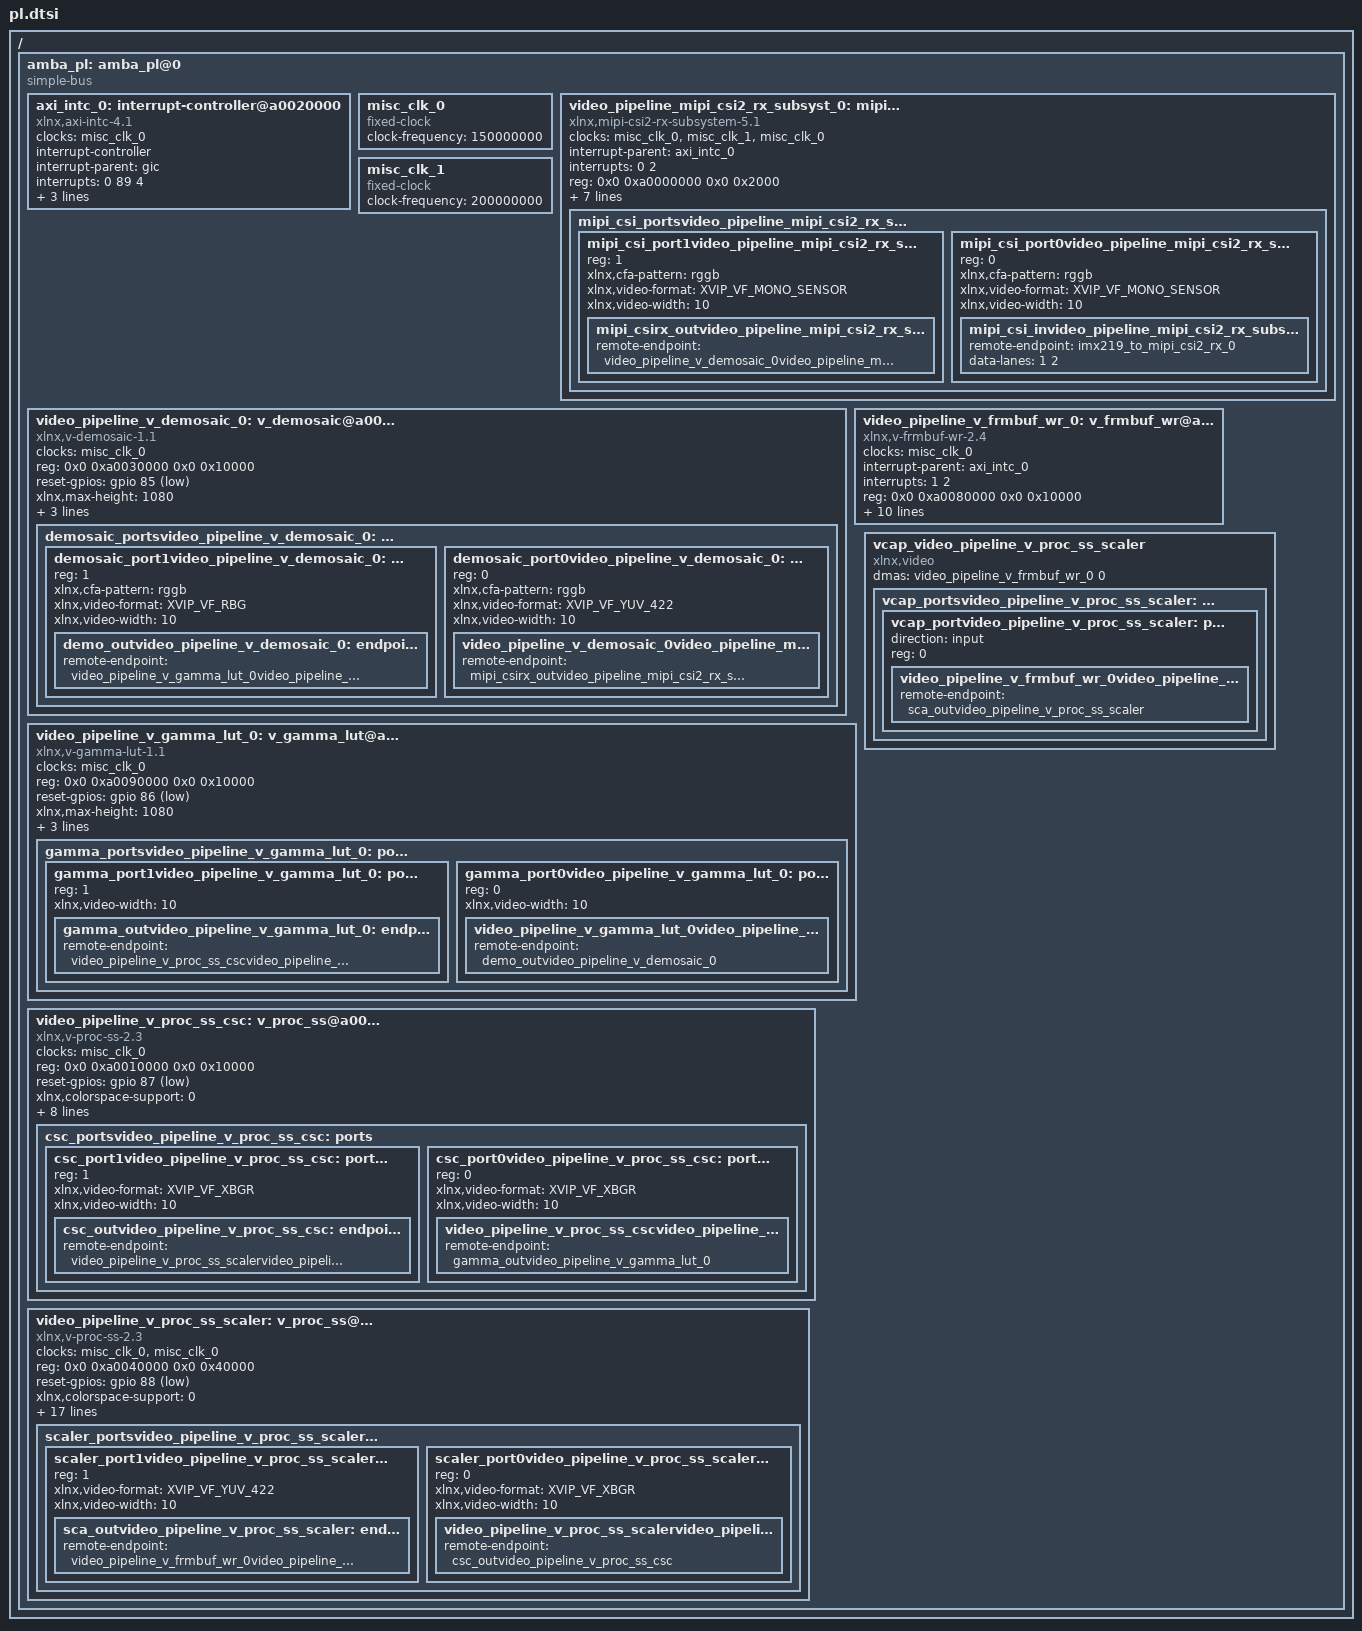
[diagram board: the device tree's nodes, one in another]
/*
 * CAUTION: This file is automatically generated by Xilinx.
 * Version: XSCT 2022.1
 * Today is: Tue Aug 23 20:26:12 2022
 */

#include <dt-bindings/media/xilinx-vip.h>

/ {
	amba_pl: amba_pl@0 {
		#address-cells = <2>;
		#size-cells = <2>;
		compatible = "simple-bus";
		ranges ;
		axi_intc_0: interrupt-controller@a0020000 {
			#interrupt-cells = <2>;
			clock-names = "s_axi_aclk";
			clocks = <&misc_clk_0>;
			compatible = "xlnx,axi-intc-4.1", "xlnx,xps-intc-1.00.a";
			interrupt-controller ;
			interrupt-names = "irq";
			interrupt-parent = <&gic>;
			interrupts = <0 89 4>;
			reg = <0x0 0xa0020000 0x0 0x10000>;
			xlnx,kind-of-intr = <0x0>;
			xlnx,num-intr-inputs = <0x2>;
		};
		misc_clk_0: misc_clk_0 {
			#clock-cells = <0>;
			clock-frequency = <150000000>;
			compatible = "fixed-clock";
		};
		video_pipeline_mipi_csi2_rx_subsyst_0: mipi_csi2_rx_subsystem@a0000000 {
			clock-names = "lite_aclk", "dphy_clk_200M", "video_aclk";
			clocks = <&misc_clk_0>, <&misc_clk_1>, <&misc_clk_0>;
			compatible = "xlnx,mipi-csi2-rx-subsystem-5.1", "xlnx,mipi-csi2-rx-subsystem-5.0";
			interrupt-names = "csirxss_csi_irq";
			interrupt-parent = <&axi_intc_0>;
			interrupts = <0 2>;
			reg = <0x0 0xa0000000 0x0 0x2000>;
			xlnx,axis-tdata-width = <32>;
			xlnx,csi-pxl-format = <0x2b>;
			xlnx,dphy-present ;
			xlnx,max-lanes = <2>;
			xlnx,ppc = <1>;
			xlnx,vc = <4>;
			xlnx,vfb ;
			mipi_csi_portsvideo_pipeline_mipi_csi2_rx_subsyst_0: ports {
				#address-cells = <1>;
				#size-cells = <0>;
				mipi_csi_port1video_pipeline_mipi_csi2_rx_subsyst_0: port@1 {
					/* Fill cfa-pattern=rggb for raw data types, other fields video-format and video-width user needs to fill */
					reg = <1>;
					xlnx,cfa-pattern = "rggb";
					xlnx,video-format = <XVIP_VF_MONO_SENSOR>;
					xlnx,video-width = <10>;
					mipi_csirx_outvideo_pipeline_mipi_csi2_rx_subsyst_0: endpoint {
						remote-endpoint = <&video_pipeline_v_demosaic_0video_pipeline_mipi_csi2_rx_subsyst_0>;
					};
				};
				mipi_csi_port0video_pipeline_mipi_csi2_rx_subsyst_0: port@0 {
					/* Fill cfa-pattern=rggb for raw data types, other fields video-format,video-width user needs to fill */
					/* User need to add something like remote-endpoint=<&out> under the node csiss_in:endpoint */
					reg = <0>;
					xlnx,cfa-pattern = "rggb";
					xlnx,video-format = <XVIP_VF_MONO_SENSOR>;
					xlnx,video-width = <10>;
					mipi_csi_invideo_pipeline_mipi_csi2_rx_subsyst_0: endpoint {
						remote-endpoint = <&imx219_to_mipi_csi2_rx_0>;
						data-lanes = <1 2>;
					};
				};
			};
		};
		misc_clk_1: misc_clk_1 {
			#clock-cells = <0>;
			clock-frequency = <200000000>;
			compatible = "fixed-clock";
		};
		video_pipeline_v_demosaic_0: v_demosaic@a0030000 {
			clock-names = "ap_clk";
			clocks = <&misc_clk_0>;
			compatible = "xlnx,v-demosaic-1.1", "xlnx,v-demosaic";
			reg = <0x0 0xa0030000 0x0 0x10000>;
			reset-gpios = <&gpio 85 1>;
			xlnx,max-height = <1080>;
			xlnx,max-width = <1920>;
			xlnx,s-axi-ctrl-addr-width = <0x6>;
			xlnx,s-axi-ctrl-data-width = <0x20>;
			demosaic_portsvideo_pipeline_v_demosaic_0: ports {
				#address-cells = <1>;
				#size-cells = <0>;
				demosaic_port1video_pipeline_v_demosaic_0: port@1 {
					/* For cfa-pattern=rggb user needs to fill as per BAYER format */
					reg = <1>;
					xlnx,cfa-pattern = "rggb";
					xlnx,video-format = <XVIP_VF_RBG>;
					xlnx,video-width = <10>;
					demo_outvideo_pipeline_v_demosaic_0: endpoint {
						remote-endpoint = <&video_pipeline_v_gamma_lut_0video_pipeline_v_demosaic_0>;
					};
				};
				demosaic_port0video_pipeline_v_demosaic_0: port@0 {
					/* For cfa-pattern=rggb user needs to fill as per BAYER format */
					reg = <0>;
					xlnx,cfa-pattern = "rggb";
					xlnx,video-format = <XVIP_VF_YUV_422>;
					xlnx,video-width = <10>;
					video_pipeline_v_demosaic_0video_pipeline_mipi_csi2_rx_subsyst_0: endpoint {
						remote-endpoint = <&mipi_csirx_outvideo_pipeline_mipi_csi2_rx_subsyst_0>;
					};
				};
			};
		};
		video_pipeline_v_frmbuf_wr_0: v_frmbuf_wr@a0080000 {
			#dma-cells = <1>;
			clock-names = "ap_clk";
			clocks = <&misc_clk_0>;
			compatible = "xlnx,v-frmbuf-wr-2.4", "xlnx,axi-frmbuf-wr-v2.2";
			interrupt-names = "interrupt";
			interrupt-parent = <&axi_intc_0>;
			interrupts = <1 2>;
			reg = <0x0 0xa0080000 0x0 0x10000>;
			reset-gpios = <&gpio 89 1>;
			xlnx,dma-addr-width = <64>;
			xlnx,dma-align = <8>;
			xlnx,max-height = <1080>;
			xlnx,max-width = <1920>;
			xlnx,pixels-per-clock = <1>;
			xlnx,s-axi-ctrl-addr-width = <0x7>;
			xlnx,s-axi-ctrl-data-width = <0x20>;
			xlnx,vid-formats = "uyvy", "y8", "yuyv";
			xlnx,video-width = <10>;
		};
		video_pipeline_v_gamma_lut_0: v_gamma_lut@a0090000 {
			clock-names = "ap_clk";
			clocks = <&misc_clk_0>;
			compatible = "xlnx,v-gamma-lut-1.1", "xlnx,v-gamma-lut";
			reg = <0x0 0xa0090000 0x0 0x10000>;
			reset-gpios = <&gpio 86 1>;
			xlnx,max-height = <1080>;
			xlnx,max-width = <1920>;
			xlnx,s-axi-ctrl-addr-width = <13>;
			xlnx,s-axi-ctrl-data-width = <32>;
			gamma_portsvideo_pipeline_v_gamma_lut_0: ports {
				#address-cells = <1>;
				#size-cells = <0>;
				gamma_port1video_pipeline_v_gamma_lut_0: port@1 {
					reg = <1>;
					xlnx,video-width = <10>;
					gamma_outvideo_pipeline_v_gamma_lut_0: endpoint {
						remote-endpoint = <&video_pipeline_v_proc_ss_cscvideo_pipeline_v_gamma_lut_0>;
					};
				};
				gamma_port0video_pipeline_v_gamma_lut_0: port@0 {
					reg = <0>;
					xlnx,video-width = <10>;
					video_pipeline_v_gamma_lut_0video_pipeline_v_demosaic_0: endpoint {
						remote-endpoint = <&demo_outvideo_pipeline_v_demosaic_0>;
					};
				};
			};
		};
		video_pipeline_v_proc_ss_csc: v_proc_ss@a0010000 {
			clock-names = "aclk";
			clocks = <&misc_clk_0>;
			compatible = "xlnx,v-proc-ss-2.3", "xlnx,vpss-csc", "xlnx,v-vpss-csc";
			reg = <0x0 0xa0010000 0x0 0x10000>;
			reset-gpios = <&gpio 87 1>;
			xlnx,colorspace-support = <0>;
			xlnx,csc-enable-window = "false";
			xlnx,max-height = <1080>;
			xlnx,max-width = <1920>;
			xlnx,num-video-components = <3>;
			xlnx,samples-per-clk = <1>;
			xlnx,topology = <3>;
			xlnx,use-uram = <0>;
			xlnx,video-width = <10>;
			csc_portsvideo_pipeline_v_proc_ss_csc: ports {
				#address-cells = <1>;
				#size-cells = <0>;
				csc_port1video_pipeline_v_proc_ss_csc: port@1 {
					/* For xlnx,video-format user needs to fill as per their requirement */
					reg = <1>;
					xlnx,video-format = <XVIP_VF_XBGR>;
					xlnx,video-width = <10>;
					csc_outvideo_pipeline_v_proc_ss_csc: endpoint {
						remote-endpoint = <&video_pipeline_v_proc_ss_scalervideo_pipeline_v_proc_ss_csc>;
					};
				};
				csc_port0video_pipeline_v_proc_ss_csc: port@0 {
					/* For xlnx,video-format user needs to fill as per their requirement */
					reg = <0>;
					xlnx,video-format = <XVIP_VF_XBGR>;
					xlnx,video-width = <10>;
					video_pipeline_v_proc_ss_cscvideo_pipeline_v_gamma_lut_0: endpoint {
						remote-endpoint = <&gamma_outvideo_pipeline_v_gamma_lut_0>;
					};
				};
			};
		};
		video_pipeline_v_proc_ss_scaler: v_proc_ss@a0040000 {
			clock-names = "aclk_axis", "aclk_ctrl";
			clocks = <&misc_clk_0>, <&misc_clk_0>;
			compatible = "xlnx,v-proc-ss-2.3", "xlnx,vpss-scaler-2.2", "xlnx,v-vpss-scaler-2.2", "xlnx,vpss-scaler";
			reg = <0x0 0xa0040000 0x0 0x40000>;
			reset-gpios = <&gpio 88 1>;
			xlnx,colorspace-support = <0>;
			xlnx,csc-enable-window = "true";
			xlnx,enable-csc = "true";
			xlnx,h-scaler-phases = <64>;
			xlnx,h-scaler-taps = <8>;
			xlnx,max-height = <1080>;
			xlnx,max-num-phases = <64>;
			xlnx,max-width = <1920>;
			xlnx,num-hori-taps = <8>;
			xlnx,num-vert-taps = <8>;
			xlnx,pix-per-clk = <1>;
			xlnx,samples-per-clk = <1>;
			xlnx,scaler-algorithm = <2>;
			xlnx,topology = <0>;
			xlnx,use-uram = <0>;
			xlnx,v-scaler-phases = <64>;
			xlnx,v-scaler-taps = <8>;
			xlnx,video-width = <10>;
			scaler_portsvideo_pipeline_v_proc_ss_scaler: ports {
				#address-cells = <1>;
				#size-cells = <0>;
				scaler_port1video_pipeline_v_proc_ss_scaler: port@1 {
					/* For xlnx,video-format user needs to fill as per their requirement */
					reg = <1>;
					xlnx,video-format = <XVIP_VF_YUV_422>;
					xlnx,video-width = <10>;
					sca_outvideo_pipeline_v_proc_ss_scaler: endpoint {
						remote-endpoint = <&video_pipeline_v_frmbuf_wr_0video_pipeline_v_proc_ss_scaler>;
					};
				};
				scaler_port0video_pipeline_v_proc_ss_scaler: port@0 {
					/* For xlnx,video-format user needs to fill as per their requirement */
					reg = <0>;
					xlnx,video-format = <XVIP_VF_XBGR>;
					xlnx,video-width = <10>;
					video_pipeline_v_proc_ss_scalervideo_pipeline_v_proc_ss_csc: endpoint {
						remote-endpoint = <&csc_outvideo_pipeline_v_proc_ss_csc>;
					};
				};
			};
		};
		vcap_video_pipeline_v_proc_ss_scaler {
			compatible = "xlnx,video";
			dma-names = "port0";
			dmas = <&video_pipeline_v_frmbuf_wr_0 0>;
			vcap_portsvideo_pipeline_v_proc_ss_scaler: ports {
				#address-cells = <1>;
				#size-cells = <0>;
				vcap_portvideo_pipeline_v_proc_ss_scaler: port@0 {
					direction = "input";
					reg = <0>;
					video_pipeline_v_frmbuf_wr_0video_pipeline_v_proc_ss_scaler: endpoint {
						remote-endpoint = <&sca_outvideo_pipeline_v_proc_ss_scaler>;
					};
				};
			};
		};
	};
};
